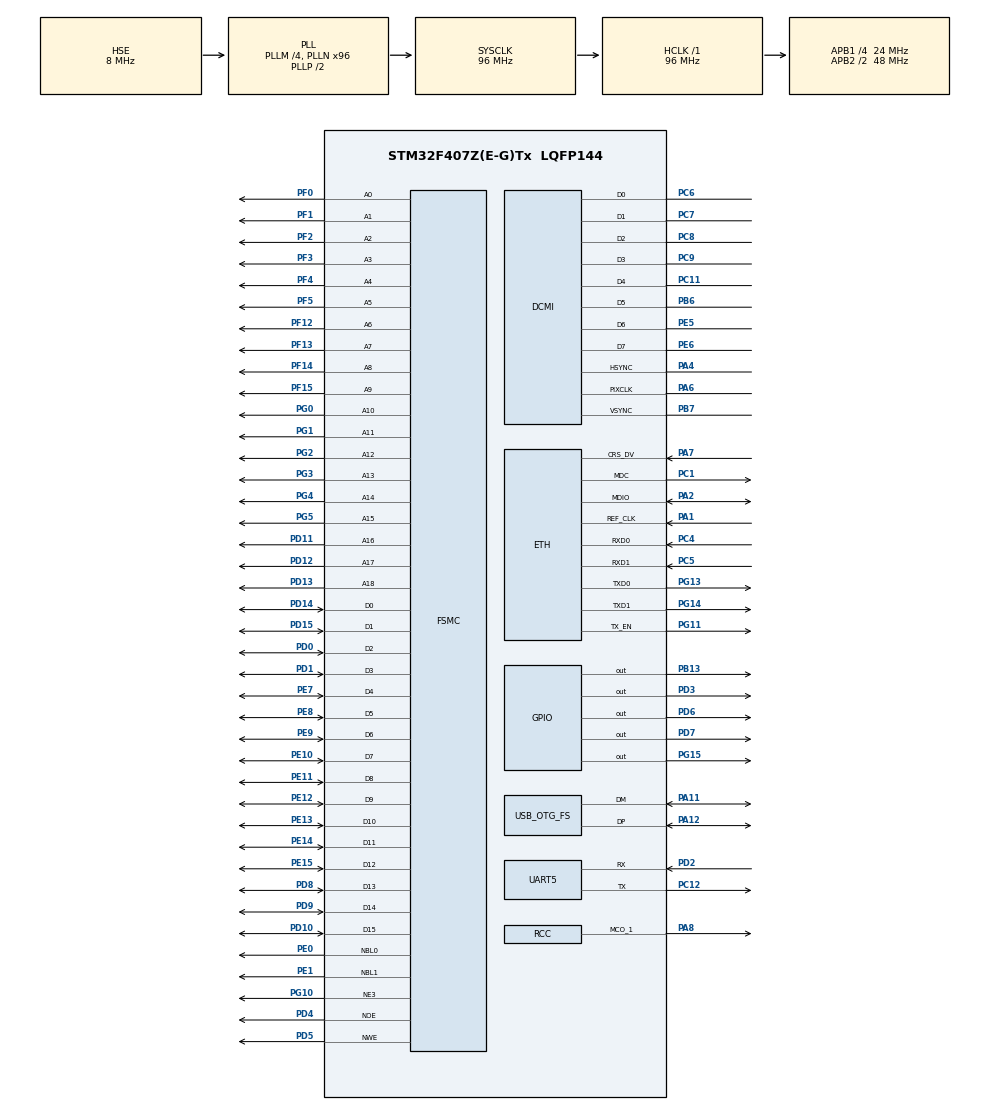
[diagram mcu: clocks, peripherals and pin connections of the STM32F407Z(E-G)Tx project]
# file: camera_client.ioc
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DCMI.CaptureRate=DCMI_CR_ALL_FRAME
DCMI.JPEGMode=DCMI_JPEG_DISABLE
DCMI.PCKPolarity=DCMI_PCKPOLARITY_RISING
DCMI.VSPolarity=DCMI_VSPOLARITY_LOW
Dma.DCMI.0.Direction=DMA_PERIPH_TO_MEMORY
Dma.DCMI.0.FIFOMode=DMA_FIFOMODE_ENABLE
Dma.DCMI.0.FIFOThreshold=DMA_FIFO_THRESHOLD_HALFFULL
Dma.DCMI.0.Instance=DMA2_Stream1
Dma.DCMI.0.MemBurst=DMA_MBURST_SINGLE
Dma.DCMI.0.MemDataAlignment=DMA_MDATAALIGN_WORD
Dma.DCMI.0.MemInc=DMA_MINC_ENABLE
Dma.DCMI.0.Mode=DMA_CIRCULAR
Dma.DCMI.0.PeriphBurst=DMA_PBURST_SINGLE
Dma.DCMI.0.PeriphDataAlignment=DMA_PDATAALIGN_WORD
Dma.DCMI.0.PeriphInc=DMA_PINC_DISABLE
Dma.DCMI.0.Priority=DMA_PRIORITY_HIGH
Dma.Request0=DCMI
ETH.MediaInterface=ETH_MEDIA_INTERFACE_RMII
ETH.PHY_DUPLEX_STATUS=0x0010
ETH.PHY_Name_RMII=DP83848_PHY_ADDRESS
ETH.PHY_SPEED_STATUS=0x0004
ETH.PHY_SR=0x31
FATFS._MAX_SS=4096
FSMC.AddressSetupTime3=5
FSMC.BusTurnAroundDuration3=0
FSMC.DataSetupTime3=7
FSMC.WriteOperation3=FSMC_WRITE_OPERATION_ENABLE
LWIP.GATEWAY_ADDRESS=192.168.001.001
LWIP.IP_ADDRESS=192.168.001.201
LWIP.LWIP_DHCP=0
LWIP.LWIP_NETIF_LINK_CALLBACK=0
LWIP.LWIP_NETIF_STATUS_CALLBACK=1
LWIP.MEMP_NUM_RAW_PCB=7
LWIP.MEMP_NUM_TCP_PCB=5
LWIP.MEMP_NUM_TCP_SEG=1000
LWIP.MEM_SIZE=30*1024
LWIP.NETMASK_ADDRESS=255.255.255.000
LWIP.PBUF_POOL_BUFSIZE=1024
LWIP.PBUF_POOL_SIZE=16
LWIP.TCP_MSS=1024
LWIP.TCP_SND_BUF=4096
LWIP.TCP_SND_QUEUELEN=1000
LWIP.TCP_WND=4096
LWIP.Version=v2.1.2_Cube
Mcu.Family=STM32F4
Mcu.Name=STM32F407Z(E-G)Tx
Mcu.Package=LQFP144
NVIC.DCMI_IRQn=true\:2\:0\:true\:false\:true\:true\:true
NVIC.DMA2_Stream1_IRQn=true\:3\:0\:true\:false\:true\:false\:true
NVIC.ETH_IRQn=true\:3\:0\:true\:false\:true\:true\:true
NVIC.OTG_FS_IRQn=true\:6\:0\:true\:false\:true\:false\:true
NVIC.PriorityGroup=NVIC_PRIORITYGROUP_4
PA1.Mode=RMII
PA1.Signal=ETH_REF_CLK
PA11.Mode=Host_Only
PA11.Signal=USB_OTG_FS_DM
PA12.Mode=Host_Only
PA12.Signal=USB_OTG_FS_DP
PA2.Mode=RMII
PA2.Signal=ETH_MDIO
PA4.Mode=Slave_8_bits_External_Synchro
PA4.Signal=DCMI_HSYNC
PA6.Mode=Slave_8_bits_External_Synchro
PA6.Signal=DCMI_PIXCLK
PA7.Mode=RMII
PA7.Signal=ETH_CRS_DV
PA8.Mode=Clock-out-1
PA8.Signal=RCC_MCO_1
PB13.PinState=GPIO_PIN_SET
PB13.Signal=GPIO_Output
PB6.Mode=Slave_8_bits_External_Synchro
PB6.Signal=DCMI_D5
PB7.Mode=Slave_8_bits_External_Synchro
PB7.Signal=DCMI_VSYNC
PC1.Mode=RMII
PC1.Signal=ETH_MDC
PC11.Mode=Slave_8_bits_External_Synchro
PC11.Signal=DCMI_D4
PC12.Mode=Asynchronous
PC12.Signal=UART5_TX
PC4.Mode=RMII
PC4.Signal=ETH_RXD0
PC5.Mode=RMII
PC5.Signal=ETH_RXD1
PC6.Mode=Slave_8_bits_External_Synchro
PC6.Signal=DCMI_D0
PC7.Mode=Slave_8_bits_External_Synchro
PC7.Signal=DCMI_D1
PC8.Mode=Slave_8_bits_External_Synchro
PC8.Signal=DCMI_D2
PC9.Mode=Slave_8_bits_External_Synchro
PC9.Signal=DCMI_D3
PD0.Signal=FSMC_D2_DA2
PD1.Signal=FSMC_D3_DA3
PD10.Signal=FSMC_D15_DA15
PD11.Signal=FSMC_A16_CLE
PD12.Signal=FSMC_A17_ALE
PD13.Signal=FSMC_A18
PD14.Signal=FSMC_D0_DA0
PD15.Signal=FSMC_D1_DA1
PD2.Mode=Asynchronous
PD2.Signal=UART5_RX
PD3.Signal=GPIO_Output
PD4.Signal=FSMC_NOE
PD5.Signal=FSMC_NWE
PD6.GPIO_PuPd=GPIO_PULLUP
PD6.GPIO_Speed=GPIO_SPEED_FREQ_VERY_HIGH
PD6.PinState=GPIO_PIN_SET
PD6.Signal=GPIO_Output
PD7.GPIO_PuPd=GPIO_PULLUP
PD7.GPIO_Speed=GPIO_SPEED_FREQ_VERY_HIGH
PD7.PinState=GPIO_PIN_SET
PD7.Signal=GPIO_Output
PD8.Signal=FSMC_D13_DA13
PD9.Signal=FSMC_D14_DA14
PE0.Signal=FSMC_NBL0
PE1.Signal=FSMC_NBL1
PE10.Signal=FSMC_D7_DA7
PE11.Signal=FSMC_D8_DA8
PE12.Signal=FSMC_D9_DA9
PE13.Signal=FSMC_D10_DA10
PE14.Signal=FSMC_D11_DA11
PE15.Signal=FSMC_D12_DA12
PE5.Mode=Slave_8_bits_External_Synchro
PE5.Signal=DCMI_D6
PE6.Mode=Slave_8_bits_External_Synchro
PE6.Signal=DCMI_D7
PE7.Signal=FSMC_D4_DA4
PE8.Signal=FSMC_D5_DA5
PE9.Signal=FSMC_D6_DA6
PF0.Signal=FSMC_A0
PF1.Signal=FSMC_A1
PF12.Signal=FSMC_A6
PF13.Signal=FSMC_A7
PF14.Signal=FSMC_A8
PF15.Signal=FSMC_A9
PF2.Signal=FSMC_A2
PF3.Signal=FSMC_A3
PF4.Signal=FSMC_A4
PF5.Signal=FSMC_A5
PG0.Signal=FSMC_A10
PG1.Signal=FSMC_A11
PG10.Mode=NorPsramChipSelect3_3
PG10.Signal=FSMC_NE3
PG11.Mode=RMII
PG11.Signal=ETH_TX_EN
PG13.Mode=RMII
PG13.Signal=ETH_TXD0
PG14.Mode=RMII
PG14.Signal=ETH_TXD1
PG15.GPIO_PuPd=GPIO_PULLUP
PG15.GPIO_Speed=GPIO_SPEED_FREQ_HIGH
PG15.PinState=GPIO_PIN_SET
PG15.Signal=GPIO_Output
PG2.Signal=FSMC_A12
PG3.Signal=FSMC_A13
PG4.Signal=FSMC_A14
PG5.Signal=FSMC_A15
PH0-OSC_IN.Mode=HSE-External-Oscillator
PH0-OSC_IN.Signal=RCC_OSC_IN
PH1-OSC_OUT.Mode=HSE-External-Oscillator
PH1-OSC_OUT.Signal=RCC_OSC_OUT
ProjectManager.HeapSize=0x1000
ProjectManager.StackSize=0x1000
ProjectManager.TargetToolchain=STM32CubeIDE
RCC.48MHZClocksFreq_Value=48000000
RCC.AHBFreq_Value=96000000
RCC.APB1CLKDivider=RCC_HCLK_DIV4
RCC.APB1Freq_Value=24000000
RCC.APB1TimFreq_Value=48000000
RCC.APB2CLKDivider=RCC_HCLK_DIV2
RCC.APB2Freq_Value=48000000
RCC.APB2TimFreq_Value=96000000
RCC.CortexFreq_Value=96000000
RCC.HCLKFreq_Value=96000000
RCC.HSE_VALUE=8000000
RCC.HSI_VALUE=16000000
RCC.LSE_VALUE=32768
RCC.PLLM=4
RCC.PLLN=96
RCC.RCC_MCO1Source=RCC_MCO1SOURCE_PLLCLK
RCC.RCC_MCODiv1=RCC_MCODIV_4
RCC.SYSCLKFreq_VALUE=96000000
RCC.SYSCLKSource=RCC_SYSCLKSOURCE_PLLCLK
RCC.VCOOutputFreq_Value=192000000
SH.FSMC_A0.0=FSMC_A0,19b-a3
SH.FSMC_A1.0=FSMC_A1,19b-a3
SH.FSMC_A10.0=FSMC_A10,19b-a3
SH.FSMC_A11.0=FSMC_A11,19b-a3
SH.FSMC_A12.0=FSMC_A12,19b-a3
SH.FSMC_A13.0=FSMC_A13,19b-a3
SH.FSMC_A14.0=FSMC_A14,19b-a3
SH.FSMC_A15.0=FSMC_A15,19b-a3
SH.FSMC_A16_CLE.0=FSMC_A16,19b-a3
SH.FSMC_A17_ALE.0=FSMC_A17,19b-a3
SH.FSMC_A18.0=FSMC_A18,19b-a3
SH.FSMC_A2.0=FSMC_A2,19b-a3
SH.FSMC_A3.0=FSMC_A3,19b-a3
SH.FSMC_A4.0=FSMC_A4,19b-a3
SH.FSMC_A5.0=FSMC_A5,19b-a3
SH.FSMC_A6.0=FSMC_A6,19b-a3
SH.FSMC_A7.0=FSMC_A7,19b-a3
SH.FSMC_A8.0=FSMC_A8,19b-a3
SH.FSMC_A9.0=FSMC_A9,19b-a3
SH.FSMC_D0_DA0.0=FSMC_D0,16b-d3
SH.FSMC_D10_DA10.0=FSMC_D10,16b-d3
SH.FSMC_D11_DA11.0=FSMC_D11,16b-d3
SH.FSMC_D12_DA12.0=FSMC_D12,16b-d3
SH.FSMC_D13_DA13.0=FSMC_D13,16b-d3
SH.FSMC_D14_DA14.0=FSMC_D14,16b-d3
SH.FSMC_D15_DA15.0=FSMC_D15,16b-d3
SH.FSMC_D1_DA1.0=FSMC_D1,16b-d3
SH.FSMC_D2_DA2.0=FSMC_D2,16b-d3
SH.FSMC_D3_DA3.0=FSMC_D3,16b-d3
SH.FSMC_D4_DA4.0=FSMC_D4,16b-d3
SH.FSMC_D5_DA5.0=FSMC_D5,16b-d3
SH.FSMC_D6_DA6.0=FSMC_D6,16b-d3
SH.FSMC_D7_DA7.0=FSMC_D7,16b-d3
SH.FSMC_D8_DA8.0=FSMC_D8,16b-d3
SH.FSMC_D9_DA9.0=FSMC_D9,16b-d3
SH.FSMC_NBL0.0=FSMC_NBL0,2ByteEnable3
SH.FSMC_NBL1.0=FSMC_NBL1,2ByteEnable3
SH.FSMC_NOE.0=FSMC_NOE,Sram3
SH.FSMC_NWE.0=FSMC_NWE,Sram3
UART5.VirtualMode=Asynchronous
USB_HOST.BSP.number=1
USB_HOST.USBH_DEBUG_LEVEL-MSC_FS=3
USB_HOST.USBH_HandleTypeDef-MSC_FS=hUsbHostFS
USB_HOST.VirtualModeFS=Msc
USB_HOST0.BSP.STBoard=false
USB_HOST0.BSP.api=Unknown
USB_HOST0.BSP.i2caddr=0
USB_HOST0.BSP.instance=PB13
USB_HOST0.BSP.ip=GPIO
USB_HOST0.BSP.mode=Output
USB_HOST0.BSP.name=Drive_VBUS_FS
USB_HOST0.BSP.solution=PB13
USB_OTG_FS.VirtualMode=Host_Only
USB_OTG_FS.phy_itface=HCD_PHY_EMBEDDED
VP_FATFS_VS_USB.Mode=USB
VP_LWIP_VS_Enabled.Mode=Enabled
VP_USB_HOST_VS_USB_HOST_MSC_FS.Mode=MSC_FS
board=custom

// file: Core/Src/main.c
/* USER CODE BEGIN Header */
/**
  ******************************************************************************
  * @file           : main.c
  * @brief          : Main program body
  ******************************************************************************
  * @attention
  *
  * Copyright (c) 2024 STMicroelectronics.
  * All rights reserved.
  *
  * This software is licensed under terms that can be found in the LICENSE file
  * in the root directory of this software component.
  * If no LICENSE file comes with this software, it is provided AS-IS.
  *
  ******************************************************************************
  */
/* USER CODE END Header */
#include "main.h"
#include "fatfs.h"
#include "lwip.h"
#include "usb_host.h"

/* USER CODE BEGIN Includes */
#include "tcpClientRAW.h"
#include "ov2640.h"
#define HEIGHT 480
#define BUFFSIZE 614400
#define  MSS (1400)
extern uint8_t testsram[BUFFSIZE] ;
//static  uint32_t testsram[BUFFSIZE] __attribute__ ((aligned(4)));
void DCMI_DMA_MemInc_En(void);
void DCMI_DMA_MemInc_Den(void);
void PY_OV2640_RGB565_CONFIG(void);

uint32_t DCMI_RN = 0;  //row number
uint32_t DCMI_CN = 0;  //column number
uint32_t DCMI_RS = 0;  //row start
uint32_t DCMI_CS = 0;  //column start

uint8_t ov2640_verh = 0xff, ov2640_verl = 0xff;
HAL_StatusTypeDef dcmi_dma_status = HAL_OK;

/* USER CODE END Includes */

DCMI_HandleTypeDef hdcmi;
DMA_HandleTypeDef hdma_dcmi;

UART_HandleTypeDef huart5;

SRAM_HandleTypeDef hsram3;

void SystemClock_Config(void);
static void MX_GPIO_Init(void);
static void MX_DMA_Init(void);
static void MX_DCMI_Init(void);
static void MX_FSMC_Init(void);
static void MX_UART5_Init(void);
void MX_USB_HOST_Process(void);

/* USER CODE BEGIN 0 */

void for_delay_us(uint32_t nus)
{
    uint32_t Delay = nus * 168/4;
    do
    {
        __NOP();
    }
    while (Delay --);
}

/* USER CODE END 0 */

int main(void)
{

  /* MCU Configuration--------------------------------------------------------*/

  /* Reset of all peripherals, Initializes the Flash interface and the Systick. */
  HAL_Init();

  /* Configure the system clock */
  SystemClock_Config();

  /* Initialize all configured peripherals */
  MX_GPIO_Init();
  MX_DMA_Init();
  MX_DCMI_Init();
  MX_FSMC_Init();
  MX_LWIP_Init();
  MX_UART5_Init();
 // MX_FATFS_Init();
 // MX_USB_HOST_Init();
  /* USER CODE BEGIN 2 */
//  while(APPLICATION_READY!=Appli_state)
//	  MX_USB_HOST_Process();
	 tcp_client_init();
	//  MX_FATFS_Init();

	 PY_OV2640_RGB565_CONFIG();
	__HAL_DCMI_ENABLE_IT(&hdcmi, DCMI_IT_FRAME);//使用帧中�?????????????????????????????????????????????????????????
	 HAL_DCMI_DisableCrop (&hdcmi);
	 DCMI_RN = HEIGHT;
	 DCMI_CN = 1280;
	 DCMI_RS =0;
	 DCMI_CS = 0;
	 HAL_DCMI_ConfigCrop (&hdcmi, DCMI_CS, DCMI_RS, DCMI_CN , DCMI_RN);
	 HAL_Delay(1);
	 HAL_DCMI_EnableCrop (&hdcmi);
 	 HAL_DCMI_Start_DMA(&hdcmi, DCMI_MODE_CONTINUOUS, (uint32_t)testsram,DCMI_CN*DCMI_RN/4);

printf("hello world\n");
  /* USER CODE END 2 */

  /* Infinite loop */
  /* USER CODE BEGIN WHILE */
  while (1)
  {
	  MX_LWIP_Process();
//	  if(echo_run==1){
//
//		  echo();
//	  }
    /* USER CODE END WHILE */
    //MX_USB_HOST_Process();

  }
}

void SystemClock_Config(void)
{
  RCC_OscInitTypeDef RCC_OscInitStruct = {0};
  RCC_ClkInitTypeDef RCC_ClkInitStruct = {0};

  /** Configure the main internal regulator output voltage
  */
  __HAL_RCC_PWR_CLK_ENABLE();
  __HAL_PWR_VOLTAGESCALING_CONFIG(PWR_REGULATOR_VOLTAGE_SCALE1);
  /** Initializes the RCC Oscillators according to the specified parameters
  * in the RCC_OscInitTypeDef structure.
  */
  RCC_OscInitStruct.OscillatorType = RCC_OSCILLATORTYPE_HSE;
  RCC_OscInitStruct.HSEState = RCC_HSE_ON;
  RCC_OscInitStruct.PLL.PLLState = RCC_PLL_ON;
  RCC_OscInitStruct.PLL.PLLSource = RCC_PLLSOURCE_HSE;
  RCC_OscInitStruct.PLL.PLLM = 4;
  RCC_OscInitStruct.PLL.PLLN = 96;
  RCC_OscInitStruct.PLL.PLLP = RCC_PLLP_DIV2;
  RCC_OscInitStruct.PLL.PLLQ = 4;
  if (HAL_RCC_OscConfig(&RCC_OscInitStruct) != HAL_OK)
  {
    Error_Handler();
  }
  /** Initializes the CPU, AHB and APB buses clocks
  */
  RCC_ClkInitStruct.ClockType = RCC_CLOCKTYPE_HCLK|RCC_CLOCKTYPE_SYSCLK
                              |RCC_CLOCKTYPE_PCLK1|RCC_CLOCKTYPE_PCLK2;
  RCC_ClkInitStruct.SYSCLKSource = RCC_SYSCLKSOURCE_PLLCLK;
  RCC_ClkInitStruct.AHBCLKDivider = RCC_SYSCLK_DIV1;
  RCC_ClkInitStruct.APB1CLKDivider = RCC_HCLK_DIV4;
  RCC_ClkInitStruct.APB2CLKDivider = RCC_HCLK_DIV2;

  if (HAL_RCC_ClockConfig(&RCC_ClkInitStruct, FLASH_LATENCY_3) != HAL_OK)
  {
    Error_Handler();
  }
  HAL_RCC_MCOConfig(RCC_MCO1, RCC_MCO1SOURCE_PLLCLK, RCC_MCODIV_4);
}

static void MX_DCMI_Init(void)
{

  hdcmi.Instance = DCMI;
  hdcmi.Init.SynchroMode = DCMI_SYNCHRO_HARDWARE;
  hdcmi.Init.PCKPolarity = DCMI_PCKPOLARITY_RISING;
  hdcmi.Init.VSPolarity = DCMI_VSPOLARITY_LOW;
  hdcmi.Init.HSPolarity = DCMI_HSPOLARITY_LOW;
  hdcmi.Init.CaptureRate = DCMI_CR_ALL_FRAME;
  hdcmi.Init.ExtendedDataMode = DCMI_EXTEND_DATA_8B;
  hdcmi.Init.JPEGMode = DCMI_JPEG_DISABLE;
  if (HAL_DCMI_Init(&hdcmi) != HAL_OK)
  {
    Error_Handler();
  }
  /* USER CODE BEGIN DCMI_Init 2 */

	__HAL_DCMI_ENABLE_IT(&hdcmi,DCMI_IT_FRAME);
	__HAL_DCMI_ENABLE(&hdcmi);

  /* USER CODE END DCMI_Init 2 */

}

static void MX_UART5_Init(void)
{

  huart5.Instance = UART5;
  huart5.Init.BaudRate = 115200;
  huart5.Init.WordLength = UART_WORDLENGTH_8B;
  huart5.Init.StopBits = UART_STOPBITS_1;
  huart5.Init.Parity = UART_PARITY_NONE;
  huart5.Init.Mode = UART_MODE_TX_RX;
  huart5.Init.HwFlowCtl = UART_HWCONTROL_NONE;
  huart5.Init.OverSampling = UART_OVERSAMPLING_16;
  if (HAL_UART_Init(&huart5) != HAL_OK)
  {
    Error_Handler();
  }

}

static void MX_DMA_Init(void)
{

  /* DMA controller clock enable */
  __HAL_RCC_DMA2_CLK_ENABLE();

  /* DMA interrupt init */
  /* DMA2_Stream1_IRQn interrupt configuration */
  HAL_NVIC_SetPriority(DMA2_Stream1_IRQn, 3, 0);
  HAL_NVIC_EnableIRQ(DMA2_Stream1_IRQn);

}

static void MX_GPIO_Init(void)
{
  GPIO_InitTypeDef GPIO_InitStruct = {0};

  /* GPIO Ports Clock Enable */
  __HAL_RCC_GPIOE_CLK_ENABLE();
  __HAL_RCC_GPIOF_CLK_ENABLE();
  __HAL_RCC_GPIOH_CLK_ENABLE();
  __HAL_RCC_GPIOC_CLK_ENABLE();
  __HAL_RCC_GPIOA_CLK_ENABLE();
  __HAL_RCC_GPIOG_CLK_ENABLE();
  __HAL_RCC_GPIOB_CLK_ENABLE();
  __HAL_RCC_GPIOD_CLK_ENABLE();

  /*Configure GPIO pin Output Level */
  HAL_GPIO_WritePin(GPIOB, GPIO_PIN_13, GPIO_PIN_SET);

  /*Configure GPIO pin Output Level */
  HAL_GPIO_WritePin(GPIOD, GPIO_PIN_3, GPIO_PIN_RESET);

  /*Configure GPIO pin Output Level */
  HAL_GPIO_WritePin(GPIOD, GPIO_PIN_6|GPIO_PIN_7, GPIO_PIN_SET);

  /*Configure GPIO pin Output Level */
  HAL_GPIO_WritePin(GPIOG, GPIO_PIN_15, GPIO_PIN_SET);

  /*Configure GPIO pin : PB13 */
  GPIO_InitStruct.Pin = GPIO_PIN_13;
  GPIO_InitStruct.Mode = GPIO_MODE_OUTPUT_PP;
  GPIO_InitStruct.Pull = GPIO_NOPULL;
  GPIO_InitStruct.Speed = GPIO_SPEED_FREQ_LOW;
  HAL_GPIO_Init(GPIOB, &GPIO_InitStruct);

  /*Configure GPIO pin : PA8 */
  GPIO_InitStruct.Pin = GPIO_PIN_8;
  GPIO_InitStruct.Mode = GPIO_MODE_AF_PP;
  GPIO_InitStruct.Pull = GPIO_NOPULL;
  GPIO_InitStruct.Speed = GPIO_SPEED_FREQ_LOW;
  GPIO_InitStruct.Alternate = GPIO_AF0_MCO;
  HAL_GPIO_Init(GPIOA, &GPIO_InitStruct);

  /*Configure GPIO pin : PD3 */
  GPIO_InitStruct.Pin = GPIO_PIN_3;
  GPIO_InitStruct.Mode = GPIO_MODE_OUTPUT_PP;
  GPIO_InitStruct.Pull = GPIO_NOPULL;
  GPIO_InitStruct.Speed = GPIO_SPEED_FREQ_LOW;
  HAL_GPIO_Init(GPIOD, &GPIO_InitStruct);

  /*Configure GPIO pins : PD6 PD7 */
  GPIO_InitStruct.Pin = GPIO_PIN_6|GPIO_PIN_7;
  GPIO_InitStruct.Mode = GPIO_MODE_OUTPUT_PP;
  GPIO_InitStruct.Pull = GPIO_PULLUP;
  GPIO_InitStruct.Speed = GPIO_SPEED_FREQ_VERY_HIGH;
  HAL_GPIO_Init(GPIOD, &GPIO_InitStruct);

  /*Configure GPIO pin : PG15 */
  GPIO_InitStruct.Pin = GPIO_PIN_15;
  GPIO_InitStruct.Mode = GPIO_MODE_OUTPUT_PP;
  GPIO_InitStruct.Pull = GPIO_PULLUP;
  GPIO_InitStruct.Speed = GPIO_SPEED_FREQ_HIGH;
  HAL_GPIO_Init(GPIOG, &GPIO_InitStruct);

}

/* FSMC initialization function */
static void MX_FSMC_Init(void)
{

  FSMC_NORSRAM_TimingTypeDef Timing = {0};

  /** Perform the SRAM3 memory initialization sequence
  */
  hsram3.Instance = FSMC_NORSRAM_DEVICE;
  hsram3.Extended = FSMC_NORSRAM_EXTENDED_DEVICE;
  /* hsram3.Init */
  hsram3.Init.NSBank = FSMC_NORSRAM_BANK3;
  hsram3.Init.DataAddressMux = FSMC_DATA_ADDRESS_MUX_DISABLE;
  hsram3.Init.MemoryType = FSMC_MEMORY_TYPE_SRAM;
  hsram3.Init.MemoryDataWidth = FSMC_NORSRAM_MEM_BUS_WIDTH_16;
  hsram3.Init.BurstAccessMode = FSMC_BURST_ACCESS_MODE_DISABLE;
  hsram3.Init.WaitSignalPolarity = FSMC_WAIT_SIGNAL_POLARITY_LOW;
  hsram3.Init.WrapMode = FSMC_WRAP_MODE_DISABLE;
  hsram3.Init.WaitSignalActive = FSMC_WAIT_TIMING_BEFORE_WS;
  hsram3.Init.WriteOperation = FSMC_WRITE_OPERATION_ENABLE;
  hsram3.Init.WaitSignal = FSMC_WAIT_SIGNAL_DISABLE;
  hsram3.Init.ExtendedMode = FSMC_EXTENDED_MODE_DISABLE;
  hsram3.Init.AsynchronousWait = FSMC_ASYNCHRONOUS_WAIT_DISABLE;
  hsram3.Init.WriteBurst = FSMC_WRITE_BURST_DISABLE;
  hsram3.Init.PageSize = FSMC_PAGE_SIZE_NONE;
  /* Timing */
  Timing.AddressSetupTime = 5;
  Timing.AddressHoldTime = 15;
  Timing.DataSetupTime = 7;
  Timing.BusTurnAroundDuration = 0;
  Timing.CLKDivision = 16;
  Timing.DataLatency = 17;
  Timing.AccessMode = FSMC_ACCESS_MODE_A;
  /* ExtTiming */

  if (HAL_SRAM_Init(&hsram3, &Timing, NULL) != HAL_OK)
  {
    Error_Handler( );
  }

}

/* USER CODE BEGIN 4 */

void DCMI_DMA_MemInc_En(void) {
	HAL_DMA_DeInit(&hdma_dcmi);

	hdma_dcmi.Init.MemInc = DMA_MINC_ENABLE;
	if (HAL_DMA_Init(&hdma_dcmi) != HAL_OK) {
		Error_Handler();
	}
}

void DCMI_DMA_MemInc_Den(void) {
	HAL_DMA_DeInit(&hdma_dcmi);
	hdma_dcmi.Init.MemInc = DMA_MINC_DISABLE;
	if (HAL_DMA_Init(&hdma_dcmi) != HAL_OK) {
		Error_Handler();
	}
}

void PY_OV2640_RGB565_CONFIG(void) {
	/*Camera Interface*/
	SCCB_Rst();     //hard reset
	HAL_Delay(100);

	//SCCB_WR_Reg(0xff, 0x01);   //soft reset
	//SCCB_WR_Reg(0x12, 0x80);
	HAL_Delay(100);

	ov2640_verh = SCCB_RD_Reg(0x1c);
	HAL_Delay(50);
	ov2640_verl = SCCB_RD_Reg(0x1d);
	HAL_Delay(50);

	while ((ov2640_verh == 0xff) || (ov2640_verl == 0xff)) {
		//HAL_UART_Transmit(&huart1, &ov2640_verh, 1, 0xFFFFFF);
		HAL_Delay(500);
		//HAL_UART_Transmit(&huart1, &ov2640_verl, 1, 0xFFFFFF);
		HAL_Delay(500);
	}

	OV2640_UXGA_Init();

	//pix speed adjustment

	OV2640_RGB565_Mode();
	OV2640_OutSize_Set(640, 480);
	HAL_Delay(200);

}

/* USER CODE END 4 */

void Error_Handler(void)
{
  __disable_irq();
  while (1)
  {
  }
}
